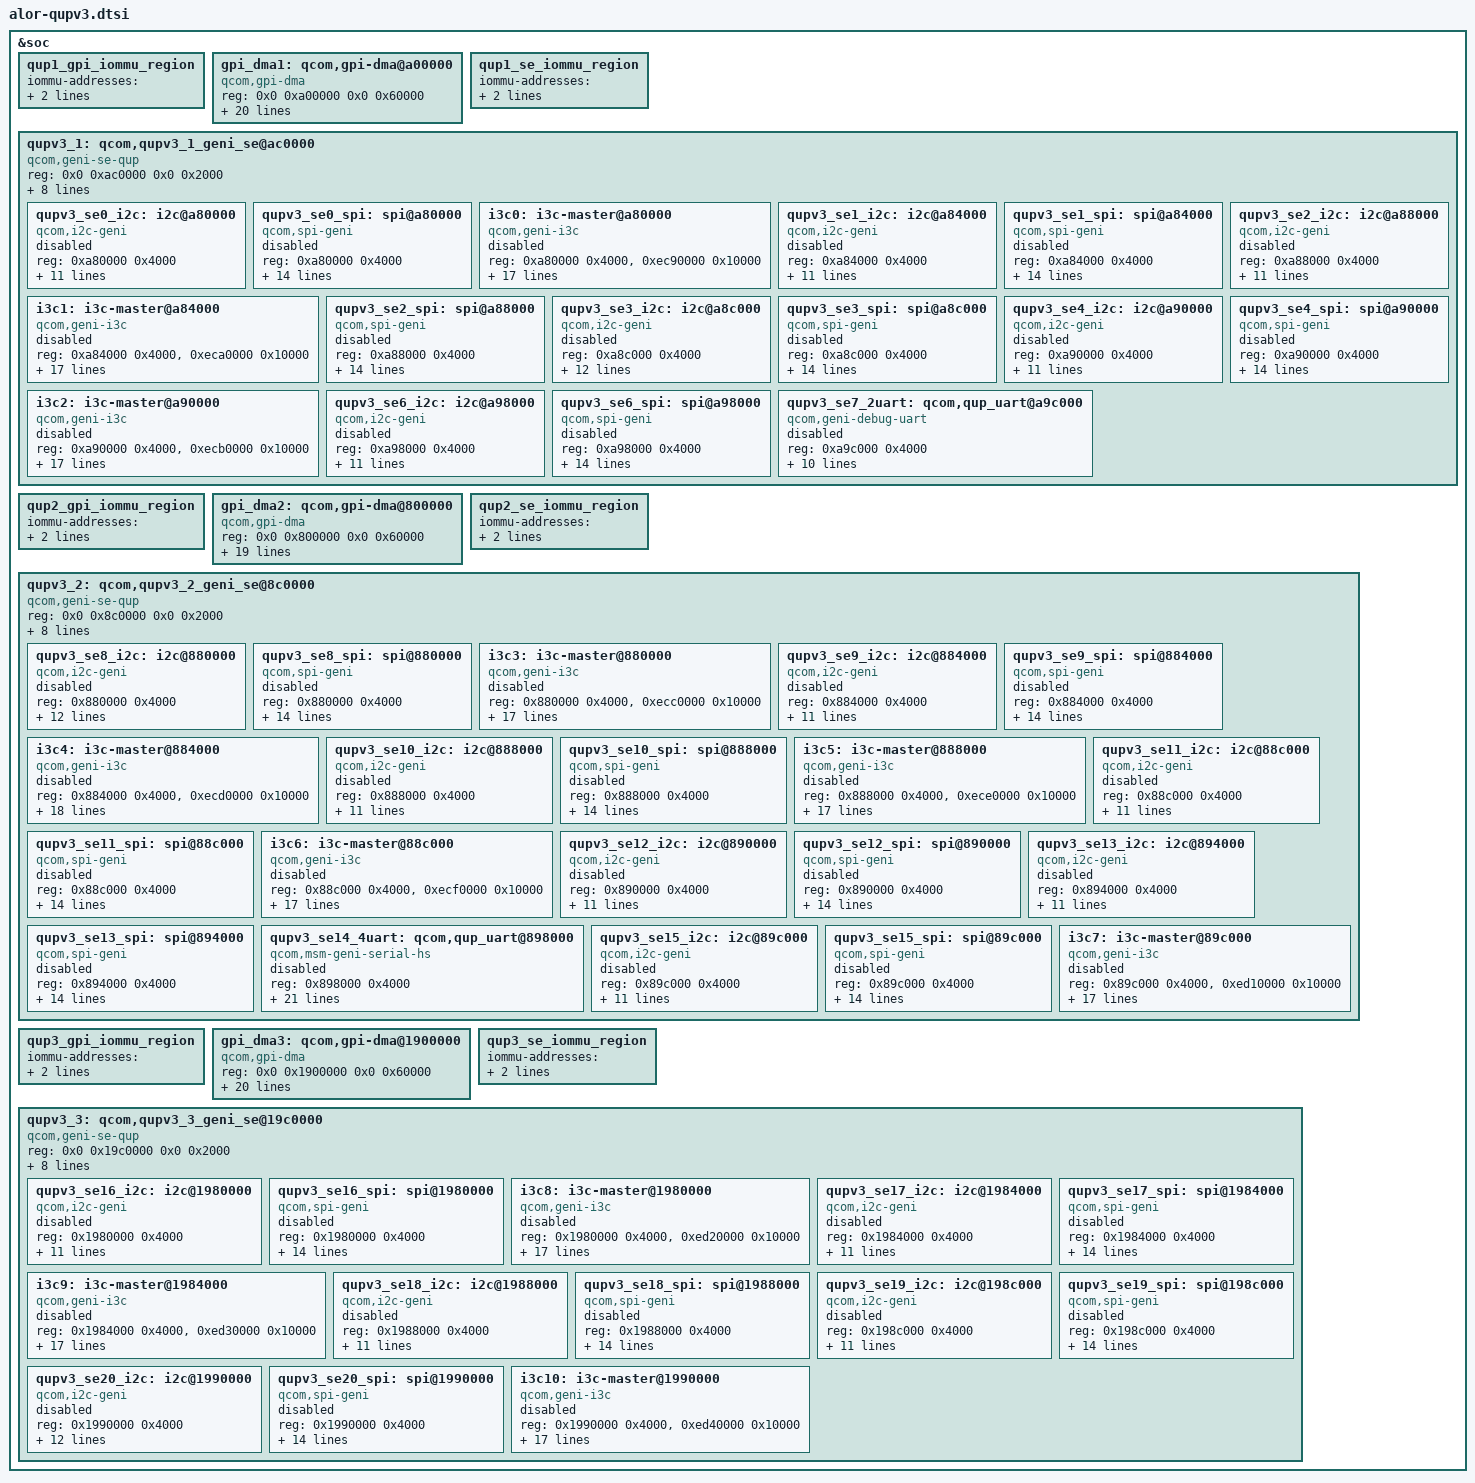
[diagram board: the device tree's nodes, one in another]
// SPDX-License-Identifier: BSD-3-Clause
/*
 * Copyright (c) 2024-2025 Qualcomm Innovation Center, Inc. All rights reserved.
 */

&soc {
	/* QUPv3 SE Instances
	 * Qup1 0: SE 0
	 * Qup1 1: SE 1
	 * Qup1 2: SE 2
	 * Qup1 3: SE 3
	 * Qup1 4: SE 4
	 * Qup1 6: SE 6
	 * Qup1 7: SE 7
	 * Qup2 0: SE 8
	 * Qup2 1: SE 9
	 * Qup2 2: SE 10
	 * Qup2 3: SE 11
	 * Qup2 4: SE 12
	 * Qup2 5: SE 13
	 * Qup2 6: SE 14
	 * Qup2 7: SE 15
	 * Qup3 0: SE 16
	 * Qup3 1: SE 17
	 * Qup3 2: SE 18
	 * Qup3 3: SE 19
	 * Qup3 4: SE 20
	 */

	qup1_gpi_iommu_region: qup1_gpi_iommu_region {
		iommu-addresses = <&gpi_dma1 0x0 0x0 0x0 0x100000>,
				  <&gpi_dma1 0x0 0x200000 0xffffffff 0xffe00000>;
	};

	/* GPI Instance */
	gpi_dma1: qcom,gpi-dma@a00000 {
		compatible = "qcom,gpi-dma";
		#dma-cells = <5>;
		reg = <0x0 0xa00000 0x0 0x60000>;
		reg-names = "gpi-top";
		iommus = <&apps_smmu 0xb6 0x0>;
		qcom,max-num-gpii = <12>;
		interrupts = <GIC_SPI 836 IRQ_TYPE_LEVEL_HIGH>,
			<GIC_SPI 837 IRQ_TYPE_LEVEL_HIGH>,
			<GIC_SPI 838 IRQ_TYPE_LEVEL_HIGH>,
			<GIC_SPI 839 IRQ_TYPE_LEVEL_HIGH>,
			<GIC_SPI 840 IRQ_TYPE_LEVEL_HIGH>,
			<GIC_SPI 841 IRQ_TYPE_LEVEL_HIGH>,
			<GIC_SPI 842 IRQ_TYPE_LEVEL_HIGH>,
			<GIC_SPI 843 IRQ_TYPE_LEVEL_HIGH>,
			<GIC_SPI 844 IRQ_TYPE_LEVEL_HIGH>,
			<GIC_SPI 845 IRQ_TYPE_LEVEL_HIGH>,
			<GIC_SPI 846 IRQ_TYPE_LEVEL_HIGH>,
			<GIC_SPI 847 IRQ_TYPE_LEVEL_HIGH>;
		qcom,static-gpii-mask = <0x1>;
		qcom,gpii-mask = <0xe>;
		qcom,ev-factor = <1>;
		memory-region = <&qup1_gpi_iommu_region>;
		qcom,gpi-ee-offset = <0x10000>;
		dma-coherent;
		status = "ok";
	};

	qup1_se_iommu_region: qup1_se_iommu_region {
		iommu-addresses =  <&qupv3_1 0x0 0x0 0x0 0x40000000>,
				   <&qupv3_1 0x0 0x50000000 0xffffffff 0xb0000000>;
	};

	/* QUPv3_1 wrapper instance */
	qupv3_1: qcom,qupv3_1_geni_se@ac0000 {
		compatible = "qcom,geni-se-qup";
		reg = <0x0 0xac0000 0x0 0x2000>;
		#address-cells = <1>;
		#size-cells = <1>;
		clock-names = "m-ahb", "s-ahb";
		clocks = <&gcc GCC_QUPV3_WRAP_1_M_AXI_CLK>,
			<&gcc GCC_QUPV3_WRAP_1_S_AHB_CLK>;
		iommus = <&apps_smmu 0xa3 0x0>;
		memory-region = <&qup1_se_iommu_region>;
		qcom,iommu-geometry = <0x0 0x40000000 0x0 0x10000000>;
		qcom,iommu-dma = "fastmap";
		dma-coherent;
		ranges;
		status = "ok";


		qupv3_se0_i2c: i2c@a80000 {
			compatible = "qcom,i2c-geni";
			reg = <0xa80000 0x4000>;
			#address-cells = <1>;
			#size-cells = <0>;
			interrupts = <GIC_SPI 828 IRQ_TYPE_LEVEL_HIGH>;
			clock-names = "se-clk";
			clocks = <&gcc GCC_QUPV3_WRAP1_S0_CLK>;
			interconnect-names = "qup-core", "qup-config", "qup-memory";
			interconnects =
			<&clk_virt MASTER_QUP_CORE_1 &clk_virt SLAVE_QUP_CORE_1>,
			<&gem_noc MASTER_APPSS_PROC &config_noc SLAVE_QUP_1>,
			<&aggre1_noc MASTER_QUP_1 &mc_virt SLAVE_EBI1>;
			pinctrl-names = "default", "sleep";
			pinctrl-0 = <&qupv3_se0_i2c_sda_active>, <&qupv3_se0_i2c_scl_active>;
			pinctrl-1 = <&qupv3_se0_i2c_sleep>;
			dmas = <&gpi_dma1 0 0 3 64 0>,
				<&gpi_dma1 1 0 3 64 0>;
			dma-names = "tx", "rx";
			status = "disabled";
		};

		qupv3_se0_spi: spi@a80000 {
			compatible = "qcom,spi-geni";
			reg = <0xa80000 0x4000>;
			#address-cells = <1>;
			#size-cells = <0>;
			reg-names = "se_phys";
			interrupts = <GIC_SPI 828 IRQ_TYPE_LEVEL_HIGH>;
			clock-names = "se-clk";
			clocks = <&gcc GCC_QUPV3_WRAP1_S0_CLK>;
			interconnect-names = "qup-core", "qup-config", "qup-memory";
			interconnects =
			<&clk_virt MASTER_QUP_CORE_1 &clk_virt SLAVE_QUP_CORE_1>,
			<&gem_noc MASTER_APPSS_PROC &config_noc SLAVE_QUP_1>,
			<&aggre1_noc MASTER_QUP_1 &mc_virt SLAVE_EBI1>;
			pinctrl-names = "default", "sleep";
			pinctrl-0 = <&qupv3_se0_spi_mosi_active>, <&qupv3_se0_spi_miso_active>,
				<&qupv3_se0_spi_clk_active>, <&qupv3_se0_spi_cs_active>;
			pinctrl-1 = <&qupv3_se0_spi_sleep>;
			dmas = <&gpi_dma1 0 0 1 64 0>,
				<&gpi_dma1 1 0 1 64 0>;
			dma-names = "tx", "rx";
			spi-max-frequency = <50000000>;
			status = "disabled";
		};

		i3c0: i3c-master@a80000 {
			compatible = "qcom,geni-i3c";
			reg = <0xa80000 0x4000>,
				<0xec90000 0x10000>;
			clock-names = "se-clk";
			clocks = <&gcc GCC_QUPV3_WRAP1_S0_CLK>;
			interconnect-names = "qup-core", "qup-config", "qup-memory";
			interconnects =
			<&clk_virt MASTER_QUP_CORE_1 &clk_virt SLAVE_QUP_CORE_1>,
			<&gem_noc MASTER_APPSS_PROC &config_noc SLAVE_QUP_1>,
			<&aggre1_noc MASTER_QUP_1 &mc_virt SLAVE_EBI1>;
			pinctrl-names = "default", "sleep", "disable";
			pinctrl-0 = <&qupv3_se0_i3c_sda_active>, <&qupv3_se0_i3c_scl_active>;
			pinctrl-1 = <&qupv3_se0_i3c_sda_sleep>, <&qupv3_se0_i3c_scl_sleep>;
			pinctrl-2 = <&qupv3_se0_i3c_disable>;
			interrupts-extended = <&intc GIC_SPI 828 IRQ_TYPE_LEVEL_HIGH>,
				<&pdc 61 IRQ_TYPE_LEVEL_HIGH>,
				<&pdc 30 IRQ_TYPE_LEVEL_HIGH>;
			#address-cells = <3>;
			#size-cells = <0>;
			qcom,ibi-ctrl-id = <2>;
			dmas = <&gpi_dma1 0 0 4 64 0>,
				<&gpi_dma1 1 0 4 64 0>;
			dma-names = "tx", "rx";
			status = "disabled";
		};

		qupv3_se1_i2c: i2c@a84000 {
			compatible = "qcom,i2c-geni";
			reg = <0xa84000 0x4000>;
			#address-cells = <1>;
			#size-cells = <0>;
			interrupts = <GIC_SPI 829 IRQ_TYPE_LEVEL_HIGH>;
			clock-names = "se-clk";
			clocks = <&gcc GCC_QUPV3_WRAP1_S1_CLK>;
			interconnect-names = "qup-core", "qup-config", "qup-memory";
			interconnects =
			<&clk_virt MASTER_QUP_CORE_1 &clk_virt SLAVE_QUP_CORE_1>,
			<&gem_noc MASTER_APPSS_PROC &config_noc SLAVE_QUP_1>,
			<&aggre1_noc MASTER_QUP_1 &mc_virt SLAVE_EBI1>;
			pinctrl-names = "default", "sleep";
			pinctrl-0 = <&qupv3_se1_i2c_sda_active>, <&qupv3_se1_i2c_scl_active>;
			pinctrl-1 = <&qupv3_se1_i2c_sleep>;
			dmas = <&gpi_dma1 0 1 3 64 0>,
				<&gpi_dma1 1 1 3 64 0>;
			dma-names = "tx", "rx";
			status = "disabled";
		};

		qupv3_se1_spi: spi@a84000 {
			compatible = "qcom,spi-geni";
			reg = <0xa84000 0x4000>;
			#address-cells = <1>;
			#size-cells = <0>;
			reg-names = "se_phys";
			interrupts = <GIC_SPI 829 IRQ_TYPE_LEVEL_HIGH>;
			clock-names = "se-clk";
			clocks = <&gcc GCC_QUPV3_WRAP1_S1_CLK>;
			interconnect-names = "qup-core", "qup-config", "qup-memory";
			interconnects =
			<&clk_virt MASTER_QUP_CORE_1 &clk_virt SLAVE_QUP_CORE_1>,
			<&gem_noc MASTER_APPSS_PROC &config_noc SLAVE_QUP_1>,
			<&aggre1_noc MASTER_QUP_1 &mc_virt SLAVE_EBI1>;
			pinctrl-names = "default", "sleep";
			pinctrl-0 = <&qupv3_se1_spi_mosi_active>, <&qupv3_se1_spi_miso_active>,
				<&qupv3_se1_spi_clk_active>, <&qupv3_se1_spi_cs_active>;
			pinctrl-1 = <&qupv3_se1_spi_sleep>;
			dmas = <&gpi_dma1 0 1 1 64 0>,
				<&gpi_dma1 1 1 1 64 0>;
			dma-names = "tx", "rx";
			spi-max-frequency = <50000000>;
			status = "disabled";
		};

		i3c1: i3c-master@a84000 {
			compatible = "qcom,geni-i3c";
			reg = <0xa84000 0x4000>,
				<0xeca0000 0x10000>;
			clock-names = "se-clk";
			clocks = <&gcc GCC_QUPV3_WRAP1_S1_CLK>;
			interconnect-names = "qup-core", "qup-config", "qup-memory";
			interconnects =
			<&clk_virt MASTER_QUP_CORE_1 &clk_virt SLAVE_QUP_CORE_1>,
			<&gem_noc MASTER_APPSS_PROC &config_noc SLAVE_QUP_1>,
			<&aggre1_noc MASTER_QUP_1 &mc_virt SLAVE_EBI1>;
			pinctrl-names = "default", "sleep", "disable";
			pinctrl-0 = <&qupv3_se1_i3c_sda_active>, <&qupv3_se1_i3c_scl_active>;
			pinctrl-1 = <&qupv3_se1_i3c_sda_sleep>, <&qupv3_se1_i3c_scl_sleep>;
			pinctrl-2 = <&qupv3_se1_i3c_disable>;
			interrupts-extended = <&intc GIC_SPI 829 IRQ_TYPE_LEVEL_HIGH>,
				<&pdc 62 IRQ_TYPE_LEVEL_HIGH>,
				<&pdc 32 IRQ_TYPE_LEVEL_HIGH>;
			#address-cells = <3>;
			#size-cells = <0>;
			qcom,ibi-ctrl-id = <11>;
			dmas = <&gpi_dma1 0 1 4 64 0>,
				<&gpi_dma1 1 1 4 64 0>;
			dma-names = "tx", "rx";
			status = "disabled";
		};

		qupv3_se2_i2c: i2c@a88000 {
			compatible = "qcom,i2c-geni";
			reg = <0xa88000 0x4000>;
			#address-cells = <1>;
			#size-cells = <0>;
			interrupts = <GIC_SPI 830 IRQ_TYPE_LEVEL_HIGH>;
			clock-names = "se-clk";
			clocks = <&gcc GCC_QUPV3_WRAP1_S2_CLK>;
			interconnect-names = "qup-core", "qup-config", "qup-memory";
			interconnects =
			<&clk_virt MASTER_QUP_CORE_1 &clk_virt SLAVE_QUP_CORE_1>,
			<&gem_noc MASTER_APPSS_PROC &config_noc SLAVE_QUP_1>,
			<&aggre1_noc MASTER_QUP_1 &mc_virt SLAVE_EBI1>;
			pinctrl-names = "default", "sleep";
			pinctrl-0 = <&qupv3_se2_i2c_sda_active>, <&qupv3_se2_i2c_scl_active>;
			pinctrl-1 = <&qupv3_se2_i2c_sleep>;
			dmas = <&gpi_dma1 0 2 3 64 0>,
				<&gpi_dma1 1 2 3 64 0>;
			dma-names = "tx", "rx";
			status = "disabled";
		};

		qupv3_se2_spi: spi@a88000 {
			compatible = "qcom,spi-geni";
			reg = <0xa88000 0x4000>;
			#address-cells = <1>;
			#size-cells = <0>;
			reg-names = "se_phys";
			interrupts = <GIC_SPI 830 IRQ_TYPE_LEVEL_HIGH>;
			clock-names = "se-clk";
			clocks = <&gcc GCC_QUPV3_WRAP1_S2_CLK>;
			interconnect-names = "qup-core", "qup-config", "qup-memory";
			interconnects =
			<&clk_virt MASTER_QUP_CORE_1 &clk_virt SLAVE_QUP_CORE_1>,
			<&gem_noc MASTER_APPSS_PROC &config_noc SLAVE_QUP_1>,
			<&aggre1_noc MASTER_QUP_1 &mc_virt SLAVE_EBI1>;
			pinctrl-names = "default", "sleep";
			pinctrl-0 = <&qupv3_se2_spi_mosi_active>, <&qupv3_se2_spi_miso_active>,
				<&qupv3_se2_spi_clk_active>, <&qupv3_se2_spi_cs_active>;
			pinctrl-1 = <&qupv3_se2_spi_sleep>;
			dmas = <&gpi_dma1 0 2 1 64 0>,
				<&gpi_dma1 1 2 1 64 0>;
			dma-names = "tx", "rx";
			spi-max-frequency = <50000000>;
			status = "disabled";
		};

		qupv3_se3_i2c: i2c@a8c000 {
			compatible = "qcom,i2c-geni";
			reg = <0xa8c000 0x4000>;
			#address-cells = <1>;
			#size-cells = <0>;
			interrupts = <GIC_SPI 831 IRQ_TYPE_LEVEL_HIGH>;
			clock-names = "se-clk";
			clocks = <&gcc GCC_QUPV3_WRAP1_S3_CLK>;
			interconnect-names = "qup-core", "qup-config", "qup-memory";
			interconnects =
			<&clk_virt MASTER_QUP_CORE_1 &clk_virt SLAVE_QUP_CORE_1>,
			<&gem_noc MASTER_APPSS_PROC &config_noc SLAVE_QUP_1>,
			<&aggre1_noc MASTER_QUP_1 &mc_virt SLAVE_EBI1>;
			pinctrl-names = "default", "sleep";
			pinctrl-0 = <&qupv3_se3_i2c_sda_active>, <&qupv3_se3_i2c_scl_active>;
			pinctrl-1 = <&qupv3_se3_i2c_sleep>;
			dmas = <&gpi_dma1 0 3 3 64 0>,
				<&gpi_dma1 1 3 3 64 0>;
			dma-names = "tx", "rx";
			qcom,shared;
			status = "disabled";
		};

		qupv3_se3_spi: spi@a8c000 {
			compatible = "qcom,spi-geni";
			reg = <0xa8c000 0x4000>;
			#address-cells = <1>;
			#size-cells = <0>;
			reg-names = "se_phys";
			interrupts = <GIC_SPI 831 IRQ_TYPE_LEVEL_HIGH>;
			clock-names = "se-clk";
			clocks = <&gcc GCC_QUPV3_WRAP1_S3_CLK>;
			interconnect-names = "qup-core", "qup-config", "qup-memory";
			interconnects =
			<&clk_virt MASTER_QUP_CORE_1 &clk_virt SLAVE_QUP_CORE_1>,
			<&gem_noc MASTER_APPSS_PROC &config_noc SLAVE_QUP_1>,
			<&aggre1_noc MASTER_QUP_1 &mc_virt SLAVE_EBI1>;
			pinctrl-names = "default", "sleep";
			pinctrl-0 = <&qupv3_se3_spi_mosi_active>, <&qupv3_se3_spi_miso_active>,
				<&qupv3_se3_spi_clk_active>, <&qupv3_se3_spi_cs_active>;
			pinctrl-1 = <&qupv3_se3_spi_sleep>;
			dmas = <&gpi_dma1 0 3 1 64 0>,
				<&gpi_dma1 1 3 1 64 0>;
			dma-names = "tx", "rx";
			spi-max-frequency = <50000000>;
			status = "disabled";
		};

		qupv3_se4_i2c: i2c@a90000 {
			compatible = "qcom,i2c-geni";
			reg = <0xa90000 0x4000>;
			#address-cells = <1>;
			#size-cells = <0>;
			interrupts = <GIC_SPI 832 IRQ_TYPE_LEVEL_HIGH>;
			clock-names = "se-clk";
			clocks = <&gcc GCC_QUPV3_WRAP1_S4_CLK>;
			interconnect-names = "qup-core", "qup-config", "qup-memory";
			interconnects =
			<&clk_virt MASTER_QUP_CORE_1 &clk_virt SLAVE_QUP_CORE_1>,
			<&gem_noc MASTER_APPSS_PROC &config_noc SLAVE_QUP_1>,
			<&aggre1_noc MASTER_QUP_1 &mc_virt SLAVE_EBI1>;
			pinctrl-names = "default", "sleep";
			pinctrl-0 = <&qupv3_se4_i2c_sda_active>, <&qupv3_se4_i2c_scl_active>;
			pinctrl-1 = <&qupv3_se4_i2c_sleep>;
			dmas = <&gpi_dma1 0 4 3 64 2>,
				<&gpi_dma1 1 4 3 64 2>;
			dma-names = "tx", "rx";
			status = "disabled";
		};

		qupv3_se4_spi: spi@a90000 {
			compatible = "qcom,spi-geni";
			reg = <0xa90000 0x4000>;
			#address-cells = <1>;
			#size-cells = <0>;
			reg-names = "se_phys";
			interrupts = <GIC_SPI 832 IRQ_TYPE_LEVEL_HIGH>;
			clock-names = "se-clk";
			clocks = <&gcc GCC_QUPV3_WRAP1_S4_CLK>;
			interconnect-names = "qup-core", "qup-config", "qup-memory";
			interconnects =
			<&clk_virt MASTER_QUP_CORE_1 &clk_virt SLAVE_QUP_CORE_1>,
			<&gem_noc MASTER_APPSS_PROC &config_noc SLAVE_QUP_1>,
			<&aggre1_noc MASTER_QUP_1 &mc_virt SLAVE_EBI1>;
			pinctrl-names = "default", "sleep";
			pinctrl-0 = <&qupv3_se4_spi_mosi_active>, <&qupv3_se4_spi_miso_active>,
				<&qupv3_se4_spi_clk_active>, <&qupv3_se4_spi_cs_active>;
			pinctrl-1 = <&qupv3_se4_spi_sleep>;
			dmas = <&gpi_dma1 0 4 1 64 2>,
				<&gpi_dma1 1 4 1 64 2>;
			dma-names = "tx", "rx";
			spi-max-frequency = <50000000>;
			status = "disabled";
		};

		i3c2: i3c-master@a90000 {
			compatible = "qcom,geni-i3c";
			reg = <0xa90000 0x4000>,
				<0xecb0000 0x10000>;
			clock-names = "se-clk";
			clocks = <&gcc GCC_QUPV3_WRAP1_S4_CLK>;
			interconnect-names = "qup-core", "qup-config", "qup-memory";
			interconnects =
			<&clk_virt MASTER_QUP_CORE_1 &clk_virt SLAVE_QUP_CORE_1>,
			<&gem_noc MASTER_APPSS_PROC &config_noc SLAVE_QUP_1>,
			<&aggre1_noc MASTER_QUP_1 &mc_virt SLAVE_EBI1>;
			pinctrl-names = "default", "sleep", "disable";
			pinctrl-0 = <&qupv3_se4_i3c_sda_active>, <&qupv3_se4_i3c_scl_active>;
			pinctrl-1 = <&qupv3_se4_i3c_sda_sleep>, <&qupv3_se4_i3c_scl_sleep>;
			pinctrl-2 = <&qupv3_se4_i3c_disable>;
			interrupts-extended = <&intc GIC_SPI 832 IRQ_TYPE_LEVEL_HIGH>,
				<&pdc 63 IRQ_TYPE_LEVEL_HIGH>,
				<&pdc 34 IRQ_TYPE_LEVEL_HIGH>;
			#address-cells = <3>;
			#size-cells = <0>;
			qcom,ibi-ctrl-id = <1>;
			dmas = <&gpi_dma1 0 4 4 64 0>,
				<&gpi_dma1 1 4 4 64 0>;
			dma-names = "tx", "rx";
			status = "disabled";
		};

		qupv3_se6_i2c: i2c@a98000 {
			compatible = "qcom,i2c-geni";
			reg = <0xa98000 0x4000>;
			#address-cells = <1>;
			#size-cells = <0>;
			interrupts = <GIC_SPI 834 IRQ_TYPE_LEVEL_HIGH>;
			clock-names = "se-clk";
			clocks = <&gcc GCC_QUPV3_WRAP1_S6_CLK>;
			interconnect-names = "qup-core", "qup-config", "qup-memory";
			interconnects =
			<&clk_virt MASTER_QUP_CORE_1 &clk_virt SLAVE_QUP_CORE_1>,
			<&gem_noc MASTER_APPSS_PROC &config_noc SLAVE_QUP_1>,
			<&aggre1_noc MASTER_QUP_1 &mc_virt SLAVE_EBI1>;
			pinctrl-names = "default", "sleep";
			pinctrl-0 = <&qupv3_se6_i2c_sda_active>, <&qupv3_se6_i2c_scl_active>;
			pinctrl-1 = <&qupv3_se6_i2c_sleep>;
			dmas = <&gpi_dma1 0 6 3 64 0>,
				<&gpi_dma1 1 6 3 64 0>;
			dma-names = "tx", "rx";
			status = "disabled";
		};

		qupv3_se6_spi: spi@a98000 {
			compatible = "qcom,spi-geni";
			reg = <0xa98000 0x4000>;
			#address-cells = <1>;
			#size-cells = <0>;
			reg-names = "se_phys";
			interrupts = <GIC_SPI 834 IRQ_TYPE_LEVEL_HIGH>;
			clock-names = "se-clk";
			clocks = <&gcc GCC_QUPV3_WRAP1_S6_CLK>;
			interconnect-names = "qup-core", "qup-config", "qup-memory";
			interconnects =
			<&clk_virt MASTER_QUP_CORE_1 &clk_virt SLAVE_QUP_CORE_1>,
			<&gem_noc MASTER_APPSS_PROC &config_noc SLAVE_QUP_1>,
			<&aggre1_noc MASTER_QUP_1 &mc_virt SLAVE_EBI1>;
			pinctrl-names = "default", "sleep";
			pinctrl-0 = <&qupv3_se6_spi_mosi_active>, <&qupv3_se6_spi_miso_active>,
				<&qupv3_se6_spi_clk_active>, <&qupv3_se6_spi_cs_active>;
			pinctrl-1 = <&qupv3_se6_spi_sleep>;
			dmas = <&gpi_dma1 0 6 1 64 0>,
				<&gpi_dma1 1 6 1 64 0>;
			dma-names = "tx", "rx";
			spi-max-frequency = <50000000>;
			status = "disabled";
		};

		/* Debug UART Instance */
		qupv3_se7_2uart: qcom,qup_uart@a9c000 {
			compatible = "qcom,geni-debug-uart";
			reg = <0xa9c000 0x4000>;
			reg-names = "se_phys";
			interrupts = <GIC_SPI 835 IRQ_TYPE_LEVEL_HIGH>;
			clock-names = "se";
			clocks = <&gcc GCC_QUPV3_WRAP1_S7_CLK>;
			interconnect-names = "qup-core", "qup-config", "qup-memory";
			interconnects =
			<&clk_virt MASTER_QUP_CORE_1 &clk_virt SLAVE_QUP_CORE_1>,
			<&gem_noc MASTER_APPSS_PROC &config_noc SLAVE_QUP_1>,
			<&aggre1_noc MASTER_QUP_1 &mc_virt SLAVE_EBI1>;
			pinctrl-names = "default", "sleep";
			pinctrl-0 = <&qupv3_se7_2uart_tx_active>, <&qupv3_se7_2uart_rx_active>;
			pinctrl-1 = <&qupv3_se7_2uart_sleep>;
			status = "disabled";
		};
	};
	qup2_gpi_iommu_region: qup2_gpi_iommu_region {
		iommu-addresses = <&gpi_dma2 0x0 0x0 0x0 0x100000>,
				  <&gpi_dma2 0x0 0x200000 0xffffffff 0xffe00000>;
	};

	/* GPI Instance */
	gpi_dma2: qcom,gpi-dma@800000 {
		compatible = "qcom,gpi-dma";
		#dma-cells = <5>;
		reg = <0x0 0x800000 0x0 0x60000>;
		reg-names = "gpi-top";
		iommus = <&apps_smmu 0x436 0x0>;
		qcom,max-num-gpii = <12>;
		interrupts = <GIC_SPI 279 IRQ_TYPE_LEVEL_HIGH>,
			<GIC_SPI 280 IRQ_TYPE_LEVEL_HIGH>,
			<GIC_SPI 281 IRQ_TYPE_LEVEL_HIGH>,
			<GIC_SPI 282 IRQ_TYPE_LEVEL_HIGH>,
			<GIC_SPI 283 IRQ_TYPE_LEVEL_HIGH>,
			<GIC_SPI 848 IRQ_TYPE_LEVEL_HIGH>,
			<GIC_SPI 849 IRQ_TYPE_LEVEL_HIGH>,
			<GIC_SPI 850 IRQ_TYPE_LEVEL_HIGH>,
			<GIC_SPI 851 IRQ_TYPE_LEVEL_HIGH>,
			<GIC_SPI 852 IRQ_TYPE_LEVEL_HIGH>,
			<GIC_SPI 853 IRQ_TYPE_LEVEL_HIGH>,
			<GIC_SPI 854 IRQ_TYPE_LEVEL_HIGH>;
		qcom,gpii-mask = <0x1f>;
		qcom,ev-factor = <1>;
		memory-region = <&qup2_gpi_iommu_region>;
		qcom,gpi-ee-offset = <0x10000>;
		dma-coherent;
		status = "ok";
	};

	qup2_se_iommu_region: qup2_se_iommu_region {
		iommu-addresses =  <&qupv3_2 0x0 0x0 0x0 0x40000000>,
				   <&qupv3_2 0x0 0x50000000 0xffffffff 0xb0000000>;
	};

	/* QUPv3_2 wrapper instance */
	qupv3_2: qcom,qupv3_2_geni_se@8c0000 {
		compatible = "qcom,geni-se-qup";
		reg = <0x0 0x8c0000 0x0 0x2000>;
		#address-cells = <1>;
		#size-cells = <1>;
		clock-names = "m-ahb", "s-ahb";
		clocks = <&gcc GCC_QUPV3_WRAP_2_M_AHB_CLK>,
			<&gcc GCC_QUPV3_WRAP_2_S_AHB_CLK>;
		iommus = <&apps_smmu 0x423 0x0>;
		memory-region = <&qup2_se_iommu_region>;
		qcom,iommu-geometry = <0x0 0x40000000 0x0 0x10000000>;
		qcom,iommu-dma = "fastmap";
		dma-coherent;
		ranges;
		status = "ok";


		qupv3_se8_i2c: i2c@880000 {
			compatible = "qcom,i2c-geni";
			reg = <0x880000 0x4000>;
			#address-cells = <1>;
			#size-cells = <0>;
			interrupts = <GIC_SPI 353 IRQ_TYPE_LEVEL_HIGH>;
			clock-names = "se-clk";
			clocks = <&gcc GCC_QUPV3_WRAP2_S0_CLK>;
			interconnect-names = "qup-core", "qup-config", "qup-memory";
			interconnects =
			<&clk_virt MASTER_QUP_CORE_2 &clk_virt SLAVE_QUP_CORE_2>,
			<&gem_noc MASTER_APPSS_PROC &config_noc SLAVE_QUP_2>,
			<&aggre2_noc MASTER_QUP_2 &mc_virt SLAVE_EBI1>;
			pinctrl-names = "default", "sleep";
			pinctrl-0 = <&qupv3_se8_i2c_sda_active>, <&qupv3_se8_i2c_scl_active>;
			pinctrl-1 = <&qupv3_se8_i2c_sleep>;
			dmas = <&gpi_dma2 0 0 3 1024 0>,
				<&gpi_dma2 1 0 3 1024 0>;
			dma-names = "tx", "rx";
			status = "disabled";
		};

		qupv3_se8_spi: spi@880000 {
			compatible = "qcom,spi-geni";
			reg = <0x880000 0x4000>;
			#address-cells = <1>;
			#size-cells = <0>;
			reg-names = "se_phys";
			interrupts = <GIC_SPI 353 IRQ_TYPE_LEVEL_HIGH>;
			clock-names = "se-clk";
			clocks = <&gcc GCC_QUPV3_WRAP2_S0_CLK>;
			interconnect-names = "qup-core", "qup-config", "qup-memory";
			interconnects =
			<&clk_virt MASTER_QUP_CORE_2 &clk_virt SLAVE_QUP_CORE_2>,
			<&gem_noc MASTER_APPSS_PROC &config_noc SLAVE_QUP_2>,
			<&aggre2_noc MASTER_QUP_2 &mc_virt SLAVE_EBI1>;
			pinctrl-names = "default", "sleep";
			pinctrl-0 = <&qupv3_se8_spi_mosi_active>, <&qupv3_se8_spi_miso_active>,
				<&qupv3_se8_spi_clk_active>, <&qupv3_se8_spi_cs_active>;
			pinctrl-1 = <&qupv3_se8_spi_sleep>;
			dmas = <&gpi_dma2 0 0 1 64 0>,
				<&gpi_dma2 1 0 1 64 0>;
			dma-names = "tx", "rx";
			spi-max-frequency = <50000000>;
			status = "disabled";
		};

		i3c3: i3c-master@880000 {
			compatible = "qcom,geni-i3c";
			reg = <0x880000 0x4000>,
				<0xecc0000 0x10000>;
			clock-names = "se-clk";
			clocks = <&gcc GCC_QUPV3_WRAP2_S0_CLK>;
			interconnect-names = "qup-core", "qup-config", "qup-memory";
			interconnects =
			<&clk_virt MASTER_QUP_CORE_2 &clk_virt SLAVE_QUP_CORE_2>,
			<&gem_noc MASTER_APPSS_PROC &config_noc SLAVE_QUP_2>,
			<&aggre2_noc MASTER_QUP_2 &mc_virt SLAVE_EBI1>;
			pinctrl-names = "default", "sleep", "disable";
			pinctrl-0 = <&qupv3_se8_i3c_sda_active>, <&qupv3_se8_i3c_scl_active>;
			pinctrl-1 = <&qupv3_se8_i3c_sda_sleep>, <&qupv3_se8_i3c_scl_sleep>;
			pinctrl-2 = <&qupv3_se8_i3c_disable>;
			interrupts-extended = <&intc GIC_SPI 353 IRQ_TYPE_LEVEL_HIGH>,
				<&pdc 64 IRQ_TYPE_LEVEL_HIGH>,
				<&pdc 36 IRQ_TYPE_LEVEL_HIGH>;
			#address-cells = <3>;
			#size-cells = <0>;
			qcom,ibi-ctrl-id = <3>;
			dmas = <&gpi_dma2 0 0 4 64 0>,
				<&gpi_dma2 1 0 4 64 0>;
			dma-names = "tx", "rx";
			status = "disabled";
		};

		qupv3_se9_i2c: i2c@884000 {
			compatible = "qcom,i2c-geni";
			reg = <0x884000 0x4000>;
			#address-cells = <1>;
			#size-cells = <0>;
			interrupts = <GIC_SPI 354 IRQ_TYPE_LEVEL_HIGH>;
			clock-names = "se-clk";
			clocks = <&gcc GCC_QUPV3_WRAP2_S1_CLK>;
			interconnect-names = "qup-core", "qup-config", "qup-memory";
			interconnects =
			<&clk_virt MASTER_QUP_CORE_2 &clk_virt SLAVE_QUP_CORE_2>,
			<&gem_noc MASTER_APPSS_PROC &config_noc SLAVE_QUP_2>,
			<&aggre2_noc MASTER_QUP_2 &mc_virt SLAVE_EBI1>;
			pinctrl-names = "default", "sleep";
			pinctrl-0 = <&qupv3_se9_i2c_sda_active>, <&qupv3_se9_i2c_scl_active>;
			pinctrl-1 = <&qupv3_se9_i2c_sleep>;
			dmas = <&gpi_dma2 0 1 3 64 0>,
				<&gpi_dma2 1 1 3 64 0>;
			dma-names = "tx", "rx";
			status = "disabled";
		};

		qupv3_se9_spi: spi@884000 {
			compatible = "qcom,spi-geni";
			reg = <0x884000 0x4000>;
			#address-cells = <1>;
			#size-cells = <0>;
			reg-names = "se_phys";
			interrupts = <GIC_SPI 354 IRQ_TYPE_LEVEL_HIGH>;
			clock-names = "se-clk";
			clocks = <&gcc GCC_QUPV3_WRAP2_S1_CLK>;
			interconnect-names = "qup-core", "qup-config", "qup-memory";
			interconnects =
			<&clk_virt MASTER_QUP_CORE_2 &clk_virt SLAVE_QUP_CORE_2>,
			<&gem_noc MASTER_APPSS_PROC &config_noc SLAVE_QUP_2>,
			<&aggre2_noc MASTER_QUP_2 &mc_virt SLAVE_EBI1>;
			pinctrl-names = "default", "sleep";
			pinctrl-0 = <&qupv3_se9_spi_mosi_active>, <&qupv3_se9_spi_miso_active>,
				<&qupv3_se9_spi_clk_active>, <&qupv3_se9_spi_cs_active>;
			pinctrl-1 = <&qupv3_se9_spi_sleep>;
			dmas = <&gpi_dma2 0 1 1 64 0>,
				<&gpi_dma2 1 1 1 64 0>;
			dma-names = "tx", "rx";
			spi-max-frequency = <50000000>;
			status = "disabled";
		};

		i3c4: i3c-master@884000 {
			compatible = "qcom,geni-i3c";
			reg = <0x884000 0x4000>,
				<0xecd0000 0x10000>;
			clock-names = "se-clk";
			clocks = <&gcc GCC_QUPV3_WRAP2_S1_CLK>;
			interconnect-names = "qup-core", "qup-config", "qup-memory";
			interconnects =
			<&clk_virt MASTER_QUP_CORE_2 &clk_virt SLAVE_QUP_CORE_2>,
			<&gem_noc MASTER_APPSS_PROC &config_noc SLAVE_QUP_2>,
			<&aggre2_noc MASTER_QUP_2 &mc_virt SLAVE_EBI1>;
			pinctrl-names = "default", "sleep", "disable";
			pinctrl-0 = <&qupv3_se9_i3c_sda_active>, <&qupv3_se9_i3c_scl_active>;
			pinctrl-1 = <&qupv3_se9_i3c_sda_sleep>, <&qupv3_se9_i3c_scl_sleep>;
			pinctrl-2 = <&qupv3_se9_i3c_disable>;
			interrupts-extended = <&intc GIC_SPI 354 IRQ_TYPE_LEVEL_HIGH>,
				<&pdc 65 IRQ_TYPE_LEVEL_HIGH>,
				<&pdc 47 IRQ_TYPE_LEVEL_HIGH>;
			#address-cells = <3>;
			#size-cells = <0>;
			qcom,ibi-ctrl-id = <4>;
			dmas = <&gpi_dma2 0 1 4 1024 0>,
				<&gpi_dma2 1 1 4 1024 0>;
			dma-names = "tx", "rx";
			status = "disabled";
		};

		qupv3_se10_i2c: i2c@888000 {
			compatible = "qcom,i2c-geni";
			reg = <0x888000 0x4000>;
			#address-cells = <1>;
			#size-cells = <0>;
			interrupts = <GIC_SPI 355 IRQ_TYPE_LEVEL_HIGH>;
			clock-names = "se-clk";
			clocks = <&gcc GCC_QUPV3_WRAP2_S2_CLK>;
			interconnect-names = "qup-core", "qup-config", "qup-memory";
			interconnects =
			<&clk_virt MASTER_QUP_CORE_2 &clk_virt SLAVE_QUP_CORE_2>,
			<&gem_noc MASTER_APPSS_PROC &config_noc SLAVE_QUP_2>,
			<&aggre2_noc MASTER_QUP_2 &mc_virt SLAVE_EBI1>;
			pinctrl-names = "default", "sleep";
			pinctrl-0 = <&qupv3_se10_i2c_sda_active>, <&qupv3_se10_i2c_scl_active>;
			pinctrl-1 = <&qupv3_se10_i2c_sleep>;
			dmas = <&gpi_dma2 0 2 3 64 0>,
				<&gpi_dma2 1 2 3 64 0>;
			dma-names = "tx", "rx";
			status = "disabled";
		};

		qupv3_se10_spi: spi@888000 {
			compatible = "qcom,spi-geni";
			reg = <0x888000 0x4000>;
			#address-cells = <1>;
			#size-cells = <0>;
			reg-names = "se_phys";
			interrupts = <GIC_SPI 355 IRQ_TYPE_LEVEL_HIGH>;
			clock-names = "se-clk";
			clocks = <&gcc GCC_QUPV3_WRAP2_S2_CLK>;
			interconnect-names = "qup-core", "qup-config", "qup-memory";
			interconnects =
			<&clk_virt MASTER_QUP_CORE_2 &clk_virt SLAVE_QUP_CORE_2>,
			<&gem_noc MASTER_APPSS_PROC &config_noc SLAVE_QUP_2>,
			<&aggre2_noc MASTER_QUP_2 &mc_virt SLAVE_EBI1>;
			pinctrl-names = "default", "sleep";
			pinctrl-0 = <&qupv3_se10_spi_mosi_active>, <&qupv3_se10_spi_miso_active>,
				<&qupv3_se10_spi_clk_active>, <&qupv3_se10_spi_cs_active>;
			pinctrl-1 = <&qupv3_se10_spi_sleep>;
			dmas = <&gpi_dma2 0 2 1 64 0>,
				<&gpi_dma2 1 2 1 64 0>;
			dma-names = "tx", "rx";
			spi-max-frequency = <50000000>;
			status = "disabled";
		};

		i3c5: i3c-master@888000 {
			compatible = "qcom,geni-i3c";
			reg = <0x888000 0x4000>,
				<0xece0000 0x10000>;
			clock-names = "se-clk";
			clocks = <&gcc GCC_QUPV3_WRAP2_S2_CLK>;
			interconnect-names = "qup-core", "qup-config", "qup-memory";
			interconnects =
			<&clk_virt MASTER_QUP_CORE_2 &clk_virt SLAVE_QUP_CORE_2>,
			<&gem_noc MASTER_APPSS_PROC &config_noc SLAVE_QUP_2>,
			<&aggre2_noc MASTER_QUP_2 &mc_virt SLAVE_EBI1>;
			pinctrl-names = "default", "sleep", "disable";
			pinctrl-0 = <&qupv3_se10_i3c_sda_active>, <&qupv3_se10_i3c_scl_active>;
			pinctrl-1 = <&qupv3_se10_i3c_sda_sleep>, <&qupv3_se10_i3c_scl_sleep>;
			pinctrl-2 = <&qupv3_se10_i3c_disable>;
			interrupts-extended = <&intc GIC_SPI 355 IRQ_TYPE_LEVEL_HIGH>,
				<&pdc 66 IRQ_TYPE_LEVEL_HIGH>,
				<&pdc 49 IRQ_TYPE_LEVEL_HIGH>;
			#address-cells = <3>;
			#size-cells = <0>;
			qcom,ibi-ctrl-id = <5>;
			dmas = <&gpi_dma2 0 2 4 64 0>,
				<&gpi_dma2 1 2 4 64 0>;
			dma-names = "tx", "rx";
			status = "disabled";
		};

		qupv3_se11_i2c: i2c@88c000 {
			compatible = "qcom,i2c-geni";
			reg = <0x88c000 0x4000>;
			#address-cells = <1>;
			#size-cells = <0>;
			interrupts = <GIC_SPI 356 IRQ_TYPE_LEVEL_HIGH>;
			clock-names = "se-clk";
			clocks = <&gcc GCC_QUPV3_WRAP2_S3_CLK>;
			interconnect-names = "qup-core", "qup-config", "qup-memory";
			interconnects =
			<&clk_virt MASTER_QUP_CORE_2 &clk_virt SLAVE_QUP_CORE_2>,
			<&gem_noc MASTER_APPSS_PROC &config_noc SLAVE_QUP_2>,
			<&aggre2_noc MASTER_QUP_2 &mc_virt SLAVE_EBI1>;
			pinctrl-names = "default", "sleep";
			pinctrl-0 = <&qupv3_se11_i2c_sda_active>, <&qupv3_se11_i2c_scl_active>;
			pinctrl-1 = <&qupv3_se11_i2c_sleep>;
			dmas = <&gpi_dma2 0 3 3 64 0>,
				<&gpi_dma2 1 3 3 64 0>;
			dma-names = "tx", "rx";
			status = "disabled";
		};

		qupv3_se11_spi: spi@88c000 {
			compatible = "qcom,spi-geni";
			reg = <0x88c000 0x4000>;
			#address-cells = <1>;
			#size-cells = <0>;
			reg-names = "se_phys";
			interrupts = <GIC_SPI 356 IRQ_TYPE_LEVEL_HIGH>;
			clock-names = "se-clk";
			clocks = <&gcc GCC_QUPV3_WRAP2_S3_CLK>;
			interconnect-names = "qup-core", "qup-config", "qup-memory";
			interconnects =
			<&clk_virt MASTER_QUP_CORE_2 &clk_virt SLAVE_QUP_CORE_2>,
			<&gem_noc MASTER_APPSS_PROC &config_noc SLAVE_QUP_2>,
			<&aggre2_noc MASTER_QUP_2 &mc_virt SLAVE_EBI1>;
			pinctrl-names = "default", "sleep";
			pinctrl-0 = <&qupv3_se11_spi_mosi_active>, <&qupv3_se11_spi_miso_active>,
				<&qupv3_se11_spi_clk_active>, <&qupv3_se11_spi_cs_active>;
			pinctrl-1 = <&qupv3_se11_spi_sleep>;
			dmas = <&gpi_dma2 0 3 1 64 0>,
				<&gpi_dma2 1 3 1 64 0>;
			dma-names = "tx", "rx";
			spi-max-frequency = <50000000>;
			status = "disabled";
		};

		i3c6: i3c-master@88c000 {
			compatible = "qcom,geni-i3c";
			reg = <0x88c000 0x4000>,
				<0xecf0000 0x10000>;
			clock-names = "se-clk";
			clocks = <&gcc GCC_QUPV3_WRAP2_S3_CLK>;
			interconnect-names = "qup-core", "qup-config", "qup-memory";
			interconnects =
			<&clk_virt MASTER_QUP_CORE_2 &clk_virt SLAVE_QUP_CORE_2>,
			<&gem_noc MASTER_APPSS_PROC &config_noc SLAVE_QUP_2>,
			<&aggre2_noc MASTER_QUP_2 &mc_virt SLAVE_EBI1>;
			pinctrl-names = "default", "sleep", "disable";
			pinctrl-0 = <&qupv3_se11_i3c_sda_active>, <&qupv3_se11_i3c_scl_active>;
			pinctrl-1 = <&qupv3_se11_i3c_sda_sleep>, <&qupv3_se11_i3c_scl_sleep>;
			pinctrl-2 = <&qupv3_se11_i3c_disable>;
			interrupts-extended = <&intc GIC_SPI 356 IRQ_TYPE_LEVEL_HIGH>,
				<&pdc 72 IRQ_TYPE_LEVEL_HIGH>,
				<&pdc 70 IRQ_TYPE_LEVEL_HIGH>;
			#address-cells = <3>;
			#size-cells = <0>;
			qcom,ibi-ctrl-id = <6>;
			dmas = <&gpi_dma2 0 3 4 64 0>,
				<&gpi_dma2 1 3 4 64 0>;
			dma-names = "tx", "rx";
			status = "disabled";
		};

		qupv3_se12_i2c: i2c@890000 {
			compatible = "qcom,i2c-geni";
			reg = <0x890000 0x4000>;
			#address-cells = <1>;
			#size-cells = <0>;
			interrupts = <GIC_SPI 357 IRQ_TYPE_LEVEL_HIGH>;
			clock-names = "se-clk";
			clocks = <&gcc GCC_QUPV3_WRAP2_S4_CLK>;
			interconnect-names = "qup-core", "qup-config", "qup-memory";
			interconnects =
			<&clk_virt MASTER_QUP_CORE_2 &clk_virt SLAVE_QUP_CORE_2>,
			<&gem_noc MASTER_APPSS_PROC &config_noc SLAVE_QUP_2>,
			<&aggre2_noc MASTER_QUP_2 &mc_virt SLAVE_EBI1>;
			pinctrl-names = "default", "sleep";
			pinctrl-0 = <&qupv3_se12_i2c_sda_active>, <&qupv3_se12_i2c_scl_active>;
			pinctrl-1 = <&qupv3_se12_i2c_sleep>;
			dmas = <&gpi_dma2 0 4 3 64 0>,
				<&gpi_dma2 1 4 3 64 0>;
			dma-names = "tx", "rx";
			status = "disabled";
		};

		qupv3_se12_spi: spi@890000 {
			compatible = "qcom,spi-geni";
			reg = <0x890000 0x4000>;
			#address-cells = <1>;
			#size-cells = <0>;
			reg-names = "se_phys";
			interrupts = <GIC_SPI 357 IRQ_TYPE_LEVEL_HIGH>;
			clock-names = "se-clk";
			clocks = <&gcc GCC_QUPV3_WRAP2_S4_CLK>;
			interconnect-names = "qup-core", "qup-config", "qup-memory";
			interconnects =
			<&clk_virt MASTER_QUP_CORE_2 &clk_virt SLAVE_QUP_CORE_2>,
			<&gem_noc MASTER_APPSS_PROC &config_noc SLAVE_QUP_2>,
			<&aggre2_noc MASTER_QUP_2 &mc_virt SLAVE_EBI1>;
			pinctrl-names = "default", "sleep";
			pinctrl-0 = <&qupv3_se12_spi_mosi_active>, <&qupv3_se12_spi_miso_active>,
				<&qupv3_se12_spi_clk_active>, <&qupv3_se12_spi_cs_active>;
			pinctrl-1 = <&qupv3_se12_spi_sleep>;
			dmas = <&gpi_dma2 0 4 1 64 0>,
				<&gpi_dma2 1 4 1 64 0>;
			dma-names = "tx", "rx";
			spi-max-frequency = <50000000>;
			status = "disabled";
		};

		qupv3_se13_i2c: i2c@894000 {
			compatible = "qcom,i2c-geni";
			reg = <0x894000 0x4000>;
			#address-cells = <1>;
			#size-cells = <0>;
			interrupts = <GIC_SPI 309 IRQ_TYPE_LEVEL_HIGH>;
			clock-names = "se-clk";
			clocks = <&gcc GCC_QUPV3_WRAP2_S5_CLK>;
			interconnect-names = "qup-core", "qup-config", "qup-memory";
			interconnects =
			<&clk_virt MASTER_QUP_CORE_2 &clk_virt SLAVE_QUP_CORE_2>,
			<&gem_noc MASTER_APPSS_PROC &config_noc SLAVE_QUP_2>,
			<&aggre2_noc MASTER_QUP_2 &mc_virt SLAVE_EBI1>;
			pinctrl-names = "default", "sleep";
			pinctrl-0 = <&qupv3_se13_i2c_sda_active>, <&qupv3_se13_i2c_scl_active>;
			pinctrl-1 = <&qupv3_se13_i2c_sleep>;
			dmas = <&gpi_dma2 0 5 3 64 0>,
				<&gpi_dma2 1 5 3 64 0>;
			dma-names = "tx", "rx";
			status = "disabled";
		};

		qupv3_se13_spi: spi@894000 {
			compatible = "qcom,spi-geni";
			reg = <0x894000 0x4000>;
			#address-cells = <1>;
			#size-cells = <0>;
			reg-names = "se_phys";
			interrupts = <GIC_SPI 309 IRQ_TYPE_LEVEL_HIGH>;
			clock-names = "se-clk";
			clocks = <&gcc GCC_QUPV3_WRAP2_S5_CLK>;
			interconnect-names = "qup-core", "qup-config", "qup-memory";
			interconnects =
			<&clk_virt MASTER_QUP_CORE_2 &clk_virt SLAVE_QUP_CORE_2>,
			<&gem_noc MASTER_APPSS_PROC &config_noc SLAVE_QUP_2>,
			<&aggre2_noc MASTER_QUP_2 &mc_virt SLAVE_EBI1>;
			pinctrl-names = "default", "sleep";
			pinctrl-0 = <&qupv3_se13_spi_mosi_active>, <&qupv3_se13_spi_miso_active>,
				<&qupv3_se13_spi_clk_active>, <&qupv3_se13_spi_cs_active>;
			pinctrl-1 = <&qupv3_se13_spi_sleep>;
			dmas = <&gpi_dma2 0 5 1 64 0>,
				<&gpi_dma2 1 5 1 64 0>;
			dma-names = "tx", "rx";
			spi-max-frequency = <50000000>;
			status = "disabled";
		};

		/* HS UART Instance */
		qupv3_se14_4uart: qcom,qup_uart@898000 {
			compatible = "qcom,msm-geni-serial-hs";
			reg = <0x898000 0x4000>;
			reg-names = "se_phys";
			interrupts-extended = <&intc GIC_SPI 310 IRQ_TYPE_LEVEL_HIGH>,
					<&tlmm 27 IRQ_TYPE_LEVEL_HIGH>;
			clock-names = "se-clk";
			clocks = <&gcc GCC_QUPV3_WRAP2_S6_CLK>;
			interconnect-names = "qup-core", "qup-config", "qup-memory";
			interconnects =
			<&clk_virt MASTER_QUP_CORE_2 &clk_virt SLAVE_QUP_CORE_2>,
			<&gem_noc MASTER_APPSS_PROC &config_noc SLAVE_QUP_2>,
			<&aggre2_noc MASTER_QUP_2 &mc_virt SLAVE_EBI1>;
			pinctrl-names = "default", "active", "sleep", "shutdown";
			pinctrl-0 = <&qupv3_se14_default_cts>, <&qupv3_se14_default_rts>,
			<&qupv3_se14_default_tx>, <&qupv3_se14_default_rx>;
			pinctrl-1 = <&qupv3_se14_cts>, <&qupv3_se14_rts>,
			<&qupv3_se14_tx>, <&qupv3_se14_rx_active>;
			pinctrl-2 = <&qupv3_se14_cts>, <&qupv3_se14_rts>,
			<&qupv3_se14_tx>, <&qupv3_se14_rx_wake>;
			pinctrl-3 = <&qupv3_se14_default_cts>, <&qupv3_se14_default_rts>,
			<&qupv3_se14_default_tx>, <&qupv3_se14_default_rx>;
			qcom,wakeup-byte = <0xFD>;
			qcom,suspend-ignore-children;
			status = "disabled";
		};

		qupv3_se15_i2c: i2c@89c000 {
			compatible = "qcom,i2c-geni";
			reg = <0x89c000 0x4000>;
			#address-cells = <1>;
			#size-cells = <0>;
			interrupts = <GIC_SPI 311 IRQ_TYPE_LEVEL_HIGH>;
			clock-names = "se-clk";
			clocks = <&gcc GCC_QUPV3_WRAP2_S7_CLK>;
			interconnect-names = "qup-core", "qup-config", "qup-memory";
			interconnects =
			<&clk_virt MASTER_QUP_CORE_2 &clk_virt SLAVE_QUP_CORE_2>,
			<&gem_noc MASTER_APPSS_PROC &config_noc SLAVE_QUP_2>,
			<&aggre2_noc MASTER_QUP_2 &mc_virt SLAVE_EBI1>;
			pinctrl-names = "default", "sleep";
			pinctrl-0 = <&qupv3_se15_i2c_sda_active>, <&qupv3_se15_i2c_scl_active>;
			pinctrl-1 = <&qupv3_se15_i2c_sleep>;
			dmas = <&gpi_dma2 0 7 3 64 0>,
				<&gpi_dma2 1 7 3 64 0>;
			dma-names = "tx", "rx";
			status = "disabled";
		};

		qupv3_se15_spi: spi@89c000 {
			compatible = "qcom,spi-geni";
			reg = <0x89c000 0x4000>;
			#address-cells = <1>;
			#size-cells = <0>;
			reg-names = "se_phys";
			interrupts = <GIC_SPI 311 IRQ_TYPE_LEVEL_HIGH>;
			clock-names = "se-clk";
			clocks = <&gcc GCC_QUPV3_WRAP2_S7_CLK>;
			interconnect-names = "qup-core", "qup-config", "qup-memory";
			interconnects =
			<&clk_virt MASTER_QUP_CORE_2 &clk_virt SLAVE_QUP_CORE_2>,
			<&gem_noc MASTER_APPSS_PROC &config_noc SLAVE_QUP_2>,
			<&aggre2_noc MASTER_QUP_2 &mc_virt SLAVE_EBI1>;
			pinctrl-names = "default", "sleep";
			pinctrl-0 = <&qupv3_se15_spi_mosi_active>, <&qupv3_se15_spi_miso_active>,
				<&qupv3_se15_spi_clk_active>, <&qupv3_se15_spi_cs_active>;
			pinctrl-1 = <&qupv3_se15_spi_sleep>;
			dmas = <&gpi_dma2 0 7 1 64 0>,
				<&gpi_dma2 1 7 1 64 0>;
			dma-names = "tx", "rx";
			spi-max-frequency = <50000000>;
			status = "disabled";
		};

		i3c7: i3c-master@89c000 {
			compatible = "qcom,geni-i3c";
			reg = <0x89c000 0x4000>,
				<0xed10000 0x10000>;
			clock-names = "se-clk";
			clocks = <&gcc GCC_QUPV3_WRAP2_S7_CLK>;
			interconnect-names = "qup-core", "qup-config", "qup-memory";
			interconnects =
			<&clk_virt MASTER_QUP_CORE_2 &clk_virt SLAVE_QUP_CORE_2>,
			<&gem_noc MASTER_APPSS_PROC &config_noc SLAVE_QUP_2>,
			<&aggre2_noc MASTER_QUP_2 &mc_virt SLAVE_EBI1>;
			pinctrl-names = "default", "sleep", "disable";
			pinctrl-0 = <&qupv3_se15_i3c_sda_active>, <&qupv3_se15_i3c_scl_active>;
			pinctrl-1 = <&qupv3_se15_i3c_sda_sleep>, <&qupv3_se15_i3c_scl_sleep>;
			pinctrl-2 = <&qupv3_se15_i3c_disable>;
			interrupts-extended = <&intc GIC_SPI 311 IRQ_TYPE_LEVEL_HIGH>,
				<&pdc 78 IRQ_TYPE_LEVEL_HIGH>,
				<&pdc 76 IRQ_TYPE_LEVEL_HIGH>;
			#address-cells = <3>;
			#size-cells = <0>;
			qcom,ibi-ctrl-id = <8>;
			dmas = <&gpi_dma2 0 7 4 64 0>,
				<&gpi_dma2 1 7 4 64 0>;
			dma-names = "tx", "rx";
			status = "disabled";
		};
	};

	qup3_gpi_iommu_region: qup3_gpi_iommu_region {
		iommu-addresses = <&gpi_dma3 0x0 0x0 0x0 0x100000>,
				  <&gpi_dma3 0x0 0x200000 0xffffffff 0xffe00000>;
	};

	/* GPI Instance */
	gpi_dma3: qcom,gpi-dma@1900000 {
		compatible = "qcom,gpi-dma";
		#dma-cells = <5>;
		reg = <0x0 0x1900000 0x0 0x60000>;
		reg-names = "gpi-top";
		iommus = <&apps_smmu 0x4d6 0x0>;
		qcom,max-num-gpii = <12>;
		interrupts = <GIC_SPI 588 IRQ_TYPE_LEVEL_HIGH>,
			<GIC_SPI 589 IRQ_TYPE_LEVEL_HIGH>,
			<GIC_SPI 590 IRQ_TYPE_LEVEL_HIGH>,
			<GIC_SPI 591 IRQ_TYPE_LEVEL_HIGH>,
			<GIC_SPI 592 IRQ_TYPE_LEVEL_HIGH>,
			<GIC_SPI 593 IRQ_TYPE_LEVEL_HIGH>,
			<GIC_SPI 594 IRQ_TYPE_LEVEL_HIGH>,
			<GIC_SPI 595 IRQ_TYPE_LEVEL_HIGH>,
			<GIC_SPI 596 IRQ_TYPE_LEVEL_HIGH>,
			<GIC_SPI 597 IRQ_TYPE_LEVEL_HIGH>,
			<GIC_SPI 598 IRQ_TYPE_LEVEL_HIGH>,
			<GIC_SPI 599 IRQ_TYPE_LEVEL_HIGH>;
		qcom,static-gpii-mask = <0x1>;
		qcom,gpii-mask = <0x1e>;
		qcom,ev-factor = <1>;
		memory-region = <&qup3_gpi_iommu_region>;
		qcom,gpi-ee-offset = <0x10000>;
		dma-coherent;
		status = "ok";
	};

	qup3_se_iommu_region: qup3_se_iommu_region {
		iommu-addresses =  <&qupv3_3 0x0 0x0 0x0 0x40000000>,
				   <&qupv3_3 0x0 0x50000000 0xffffffff 0xb0000000>;
	};

	/* QUPv3_3 wrapper instance */
	qupv3_3: qcom,qupv3_3_geni_se@19c0000 {
		compatible = "qcom,geni-se-qup";
		reg = <0x0 0x19c0000 0x0 0x2000>;
		#address-cells = <1>;
		#size-cells = <1>;
		clock-names = "m-ahb", "s-ahb";
		clocks = <&gcc GCC_QUPV3_WRAP_3_M_AHB_CLK>,
			<&gcc GCC_QUPV3_WRAP_3_S_AHB_CLK>;
		iommus = <&apps_smmu 0x4c3 0x0>;
		memory-region = <&qup3_se_iommu_region>;
		qcom,iommu-geometry = <0x0 0x40000000 0x0 0x10000000>;
		qcom,iommu-dma = "fastmap";
		dma-coherent;
		ranges;
		status = "ok";


		qupv3_se16_i2c: i2c@1980000 {
			compatible = "qcom,i2c-geni";
			reg = <0x1980000 0x4000>;
			#address-cells = <1>;
			#size-cells = <0>;
			interrupts = <GIC_SPI 373 IRQ_TYPE_LEVEL_HIGH>;
			clock-names = "se-clk";
			clocks = <&gcc GCC_QUPV3_WRAP3_S0_CLK>;
			interconnect-names = "qup-core", "qup-config", "qup-memory";
			interconnects =
			<&clk_virt MASTER_QUP_CORE_3 &clk_virt SLAVE_QUP_CORE_3>,
			<&gem_noc MASTER_APPSS_PROC &config_noc SLAVE_QUP_3>,
			<&aggre2_noc MASTER_QUP_3 &mc_virt SLAVE_EBI1>;
			pinctrl-names = "default", "sleep";
			pinctrl-0 = <&qupv3_se16_i2c_sda_active>, <&qupv3_se16_i2c_scl_active>;
			pinctrl-1 = <&qupv3_se16_i2c_sleep>;
			dmas = <&gpi_dma3 0 0 3 64 0>,
				<&gpi_dma3 1 0 3 64 0>;
			dma-names = "tx", "rx";
			status = "disabled";
		};

		qupv3_se16_spi: spi@1980000 {
			compatible = "qcom,spi-geni";
			reg = <0x1980000 0x4000>;
			#address-cells = <1>;
			#size-cells = <0>;
			reg-names = "se_phys";
			interrupts = <GIC_SPI 373 IRQ_TYPE_LEVEL_HIGH>;
			clock-names = "se-clk";
			clocks = <&gcc GCC_QUPV3_WRAP3_S0_CLK>;
			interconnect-names = "qup-core", "qup-config", "qup-memory";
			interconnects =
			<&clk_virt MASTER_QUP_CORE_3 &clk_virt SLAVE_QUP_CORE_3>,
			<&gem_noc MASTER_APPSS_PROC &config_noc SLAVE_QUP_3>,
			<&aggre2_noc MASTER_QUP_3 &mc_virt SLAVE_EBI1>;
			pinctrl-names = "default", "sleep";
			pinctrl-0 = <&qupv3_se16_spi_mosi_active>, <&qupv3_se16_spi_miso_active>,
				<&qupv3_se16_spi_clk_active>, <&qupv3_se16_spi_cs_active>;
			pinctrl-1 = <&qupv3_se16_spi_sleep>;
			dmas = <&gpi_dma3 0 0 1 64 0>,
				<&gpi_dma3 1 0 1 64 0>;
			dma-names = "tx", "rx";
			spi-max-frequency = <50000000>;
			status = "disabled";
		};

		i3c8: i3c-master@1980000 {
			compatible = "qcom,geni-i3c";
			reg = <0x1980000 0x4000>,
				<0xed20000 0x10000>;
			clock-names = "se-clk";
			clocks = <&gcc GCC_QUPV3_WRAP3_S0_CLK>;
			interconnect-names = "qup-core", "qup-config", "qup-memory";
			interconnects =
			<&clk_virt MASTER_QUP_CORE_3 &clk_virt SLAVE_QUP_CORE_3>,
			<&gem_noc MASTER_APPSS_PROC &config_noc SLAVE_QUP_3>,
			<&aggre2_noc MASTER_QUP_3 &mc_virt SLAVE_EBI1>;
			pinctrl-names = "default", "sleep", "disable";
			pinctrl-0 = <&qupv3_se16_i3c_sda_active>, <&qupv3_se16_i3c_scl_active>;
			pinctrl-1 = <&qupv3_se16_i3c_sda_sleep>, <&qupv3_se16_i3c_scl_sleep>;
			pinctrl-2 = <&qupv3_se16_i3c_disable>;
			interrupts-extended = <&intc GIC_SPI 373 IRQ_TYPE_LEVEL_HIGH>,
				<&pdc 83 IRQ_TYPE_LEVEL_HIGH>,
				<&pdc 81 IRQ_TYPE_LEVEL_HIGH>;
			#address-cells = <3>;
			#size-cells = <0>;
			qcom,ibi-ctrl-id = <12>;
			dmas = <&gpi_dma3 0 0 4 64 0>,
				<&gpi_dma3 1 0 4 64 0>;
			dma-names = "tx", "rx";
			status = "disabled";
		};

		qupv3_se17_i2c: i2c@1984000 {
			compatible = "qcom,i2c-geni";
			reg = <0x1984000 0x4000>;
			#address-cells = <1>;
			#size-cells = <0>;
			interrupts = <GIC_SPI 583 IRQ_TYPE_LEVEL_HIGH>;
			clock-names = "se-clk";
			clocks = <&gcc GCC_QUPV3_WRAP3_S1_CLK>;
			interconnect-names = "qup-core", "qup-config", "qup-memory";
			interconnects =
			<&clk_virt MASTER_QUP_CORE_3 &clk_virt SLAVE_QUP_CORE_3>,
			<&gem_noc MASTER_APPSS_PROC &config_noc SLAVE_QUP_3>,
			<&aggre2_noc MASTER_QUP_3 &mc_virt SLAVE_EBI1>;
			pinctrl-names = "default", "sleep";
			pinctrl-0 = <&qupv3_se17_i2c_sda_active>, <&qupv3_se17_i2c_scl_active>;
			pinctrl-1 = <&qupv3_se17_i2c_sleep>;
			dmas = <&gpi_dma3 0 1 3 64 2>,
				<&gpi_dma3 1 1 3 64 2>;
			dma-names = "tx", "rx";
			status = "disabled";
		};

		qupv3_se17_spi: spi@1984000 {
			compatible = "qcom,spi-geni";
			reg = <0x1984000 0x4000>;
			#address-cells = <1>;
			#size-cells = <0>;
			reg-names = "se_phys";
			interrupts = <GIC_SPI 583 IRQ_TYPE_LEVEL_HIGH>;
			clock-names = "se-clk";
			clocks = <&gcc GCC_QUPV3_WRAP3_S1_CLK>;
			interconnect-names = "qup-core", "qup-config", "qup-memory";
			interconnects =
			<&clk_virt MASTER_QUP_CORE_3 &clk_virt SLAVE_QUP_CORE_3>,
			<&gem_noc MASTER_APPSS_PROC &config_noc SLAVE_QUP_3>,
			<&aggre2_noc MASTER_QUP_3 &mc_virt SLAVE_EBI1>;
			pinctrl-names = "default", "sleep";
			pinctrl-0 = <&qupv3_se17_spi_mosi_active>, <&qupv3_se17_spi_miso_active>,
				<&qupv3_se17_spi_clk_active>, <&qupv3_se17_spi_cs_active>;
			pinctrl-1 = <&qupv3_se17_spi_sleep>;
			dmas = <&gpi_dma3 0 1 1 64 2>,
				<&gpi_dma3 1 1 1 64 2>;
			dma-names = "tx", "rx";
			spi-max-frequency = <50000000>;
			status = "disabled";
		};

		i3c9: i3c-master@1984000 {
			compatible = "qcom,geni-i3c";
			reg = <0x1984000 0x4000>,
				<0xed30000 0x10000>;
			clock-names = "se-clk";
			clocks = <&gcc GCC_QUPV3_WRAP3_S1_CLK>;
			interconnect-names = "qup-core", "qup-config", "qup-memory";
			interconnects =
			<&clk_virt MASTER_QUP_CORE_3 &clk_virt SLAVE_QUP_CORE_3>,
			<&gem_noc MASTER_APPSS_PROC &config_noc SLAVE_QUP_3>,
			<&aggre2_noc MASTER_QUP_3 &mc_virt SLAVE_EBI1>;
			pinctrl-names = "default", "sleep", "disable";
			pinctrl-0 = <&qupv3_se17_i3c_sda_active>, <&qupv3_se17_i3c_scl_active>;
			pinctrl-1 = <&qupv3_se17_i3c_sda_sleep>, <&qupv3_se17_i3c_scl_sleep>;
			pinctrl-2 = <&qupv3_se17_i3c_disable>;
			interrupts-extended = <&intc GIC_SPI 583 IRQ_TYPE_LEVEL_HIGH>,
				<&pdc 86 IRQ_TYPE_LEVEL_HIGH>,
				<&pdc 84 IRQ_TYPE_LEVEL_HIGH>;
			#address-cells = <3>;
			#size-cells = <0>;
			qcom,ibi-ctrl-id = <9>;
			dmas = <&gpi_dma3 0 1 4 64 0>,
				<&gpi_dma3 1 1 4 64 0>;
			dma-names = "tx", "rx";
			status = "disabled";
		};

		qupv3_se18_i2c: i2c@1988000 {
			compatible = "qcom,i2c-geni";
			reg = <0x1988000 0x4000>;
			#address-cells = <1>;
			#size-cells = <0>;
			interrupts = <GIC_SPI 584 IRQ_TYPE_LEVEL_HIGH>;
			clock-names = "se-clk";
			clocks = <&gcc GCC_QUPV3_WRAP3_S2_CLK>;
			interconnect-names = "qup-core", "qup-config", "qup-memory";
			interconnects =
			<&clk_virt MASTER_QUP_CORE_3 &clk_virt SLAVE_QUP_CORE_3>,
			<&gem_noc MASTER_APPSS_PROC &config_noc SLAVE_QUP_3>,
			<&aggre2_noc MASTER_QUP_3 &mc_virt SLAVE_EBI1>;
			pinctrl-names = "default", "sleep";
			pinctrl-0 = <&qupv3_se18_i2c_sda_active>, <&qupv3_se18_i2c_scl_active>;
			pinctrl-1 = <&qupv3_se18_i2c_sleep>;
			dmas = <&gpi_dma3 0 2 3 64 0>,
				<&gpi_dma3 1 2 3 64 0>;
			dma-names = "tx", "rx";
			status = "disabled";
		};

		qupv3_se18_spi: spi@1988000 {
			compatible = "qcom,spi-geni";
			reg = <0x1988000 0x4000>;
			#address-cells = <1>;
			#size-cells = <0>;
			reg-names = "se_phys";
			interrupts = <GIC_SPI 584 IRQ_TYPE_LEVEL_HIGH>;
			clock-names = "se-clk";
			clocks = <&gcc GCC_QUPV3_WRAP3_S2_CLK>;
			interconnect-names = "qup-core", "qup-config", "qup-memory";
			interconnects =
			<&clk_virt MASTER_QUP_CORE_3 &clk_virt SLAVE_QUP_CORE_3>,
			<&gem_noc MASTER_APPSS_PROC &config_noc SLAVE_QUP_3>,
			<&aggre2_noc MASTER_QUP_3 &mc_virt SLAVE_EBI1>;
			pinctrl-names = "default", "sleep";
			pinctrl-0 = <&qupv3_se18_spi_mosi_active>, <&qupv3_se18_spi_miso_active>,
				<&qupv3_se18_spi_clk_active>, <&qupv3_se18_spi_cs_active>;
			pinctrl-1 = <&qupv3_se18_spi_sleep>;
			dmas = <&gpi_dma3 0 2 1 64 0>,
				<&gpi_dma3 1 2 1 64 0>;
			dma-names = "tx", "rx";
			spi-max-frequency = <50000000>;
			status = "disabled";
		};

		qupv3_se19_i2c: i2c@198c000 {
			compatible = "qcom,i2c-geni";
			reg = <0x198c000 0x4000>;
			#address-cells = <1>;
			#size-cells = <0>;
			interrupts = <GIC_SPI 585 IRQ_TYPE_LEVEL_HIGH>;
			clock-names = "se-clk";
			clocks = <&gcc GCC_QUPV3_WRAP3_S3_CLK>;
			interconnect-names = "qup-core", "qup-config", "qup-memory";
			interconnects =
			<&clk_virt MASTER_QUP_CORE_3 &clk_virt SLAVE_QUP_CORE_3>,
			<&gem_noc MASTER_APPSS_PROC &config_noc SLAVE_QUP_3>,
			<&aggre2_noc MASTER_QUP_3 &mc_virt SLAVE_EBI1>;
			pinctrl-names = "default", "sleep";
			pinctrl-0 = <&qupv3_se19_i2c_sda_active>, <&qupv3_se19_i2c_scl_active>;
			pinctrl-1 = <&qupv3_se19_i2c_sleep>;
			dmas = <&gpi_dma3 0 3 3 64 0>,
				<&gpi_dma3 1 3 3 64 0>;
			dma-names = "tx", "rx";
			status = "disabled";
		};

		qupv3_se19_spi: spi@198c000 {
			compatible = "qcom,spi-geni";
			reg = <0x198c000 0x4000>;
			#address-cells = <1>;
			#size-cells = <0>;
			reg-names = "se_phys";
			interrupts = <GIC_SPI 585 IRQ_TYPE_LEVEL_HIGH>;
			clock-names = "se-clk";
			clocks = <&gcc GCC_QUPV3_WRAP3_S3_CLK>;
			interconnect-names = "qup-core", "qup-config", "qup-memory";
			interconnects =
			<&clk_virt MASTER_QUP_CORE_3 &clk_virt SLAVE_QUP_CORE_3>,
			<&gem_noc MASTER_APPSS_PROC &config_noc SLAVE_QUP_3>,
			<&aggre2_noc MASTER_QUP_3 &mc_virt SLAVE_EBI1>;
			pinctrl-names = "default", "sleep";
			pinctrl-0 = <&qupv3_se19_spi_mosi_active>, <&qupv3_se19_spi_miso_active>,
				<&qupv3_se19_spi_clk_active>, <&qupv3_se19_spi_cs_active>;
			pinctrl-1 = <&qupv3_se19_spi_sleep>;
			dmas = <&gpi_dma3 0 3 1 64 0>,
				<&gpi_dma3 1 3 1 64 0>;
			dma-names = "tx", "rx";
			spi-max-frequency = <50000000>;
			status = "disabled";
		};

		qupv3_se20_i2c: i2c@1990000 {
			compatible = "qcom,i2c-geni";
			reg = <0x1990000 0x4000>;
			#address-cells = <1>;
			#size-cells = <0>;
			interrupts = <GIC_SPI 586 IRQ_TYPE_LEVEL_HIGH>;
			clock-names = "se-clk";
			clocks = <&gcc GCC_QUPV3_WRAP3_S4_CLK>;
			interconnect-names = "qup-core", "qup-config", "qup-memory";
			interconnects =
			<&clk_virt MASTER_QUP_CORE_3 &clk_virt SLAVE_QUP_CORE_3>,
			<&gem_noc MASTER_APPSS_PROC &config_noc SLAVE_QUP_3>,
			<&aggre2_noc MASTER_QUP_3 &mc_virt SLAVE_EBI1>;
			pinctrl-names = "default", "sleep";
			pinctrl-0 = <&qupv3_se20_i2c_sda_active>, <&qupv3_se20_i2c_scl_active>;
			pinctrl-1 = <&qupv3_se20_i2c_sleep>;
			dmas = <&gpi_dma3 0 4 3 64 0>,
				<&gpi_dma3 1 4 3 64 0>;
			dma-names = "tx", "rx";
			qcom,shared;
			status = "disabled";
		};

		qupv3_se20_spi: spi@1990000 {
			compatible = "qcom,spi-geni";
			reg = <0x1990000 0x4000>;
			#address-cells = <1>;
			#size-cells = <0>;
			reg-names = "se_phys";
			interrupts = <GIC_SPI 586 IRQ_TYPE_LEVEL_HIGH>;
			clock-names = "se-clk";
			clocks = <&gcc GCC_QUPV3_WRAP3_S4_CLK>;
			interconnect-names = "qup-core", "qup-config", "qup-memory";
			interconnects =
			<&clk_virt MASTER_QUP_CORE_3 &clk_virt SLAVE_QUP_CORE_3>,
			<&gem_noc MASTER_APPSS_PROC &config_noc SLAVE_QUP_3>,
			<&aggre2_noc MASTER_QUP_3 &mc_virt SLAVE_EBI1>;
			pinctrl-names = "default", "sleep";
			pinctrl-0 = <&qupv3_se20_spi_mosi_active>, <&qupv3_se20_spi_miso_active>,
				<&qupv3_se20_spi_clk_active>, <&qupv3_se20_spi_cs_active>;
			pinctrl-1 = <&qupv3_se20_spi_sleep>;
			dmas = <&gpi_dma3 0 4 1 64 0>,
				<&gpi_dma3 1 4 1 64 0>;
			dma-names = "tx", "rx";
			spi-max-frequency = <50000000>;
			status = "disabled";
		};

		i3c10: i3c-master@1990000 {
			compatible = "qcom,geni-i3c";
			reg = <0x1990000 0x4000>,
				<0xed40000 0x10000>;
			clock-names = "se-clk";
			clocks = <&gcc GCC_QUPV3_WRAP3_S4_CLK>;
			interconnect-names = "qup-core", "qup-config", "qup-memory";
			interconnects =
			<&clk_virt MASTER_QUP_CORE_3 &clk_virt SLAVE_QUP_CORE_3>,
			<&gem_noc MASTER_APPSS_PROC &config_noc SLAVE_QUP_3>,
			<&aggre2_noc MASTER_QUP_3 &mc_virt SLAVE_EBI1>;
			pinctrl-names = "default", "sleep", "disable";
			pinctrl-0 = <&qupv3_se20_i3c_sda_active>, <&qupv3_se20_i3c_scl_active>;
			pinctrl-1 = <&qupv3_se20_i3c_sda_sleep>, <&qupv3_se20_i3c_scl_sleep>;
			pinctrl-2 = <&qupv3_se20_i3c_disable>;
			interrupts-extended = <&intc GIC_SPI 586 IRQ_TYPE_LEVEL_HIGH>,
				<&pdc 89 IRQ_TYPE_LEVEL_HIGH>,
				<&pdc 87 IRQ_TYPE_LEVEL_HIGH>;
			#address-cells = <3>;
			#size-cells = <0>;
			qcom,ibi-ctrl-id = <10>;
			dmas = <&gpi_dma3 0 4 4 64 0>,
				<&gpi_dma3 1 4 4 64 0>;
			dma-names = "tx", "rx";
			status = "disabled";
		};
	};
};
